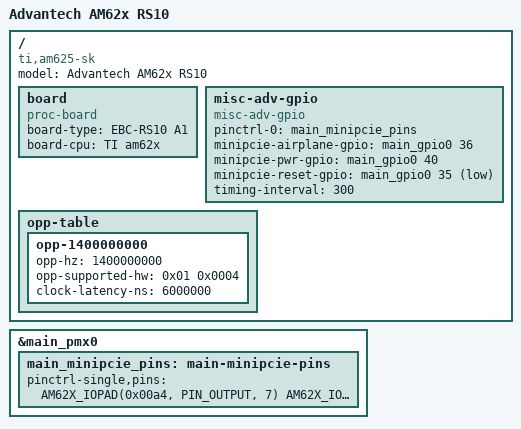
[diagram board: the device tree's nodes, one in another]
// SPDX-License-Identifier: GPL-2.0
/*
 * AM625 SK: https://www.ti.com/lit/zip/sprr448
 *
 * Copyright (C) 2021-2022 Texas Instruments Incorporated - https://www.ti.com/
 */

/dts-v1/;

#include <dt-bindings/leds/common.h>
#include <dt-bindings/gpio/gpio.h>
#include <dt-bindings/net/ti-dp83867.h>
#include "k3-am625.dtsi"
#include "k3-am62x-rs10-common.dtsi"

/ {
	compatible =  "ti,am625-sk", "ti,am625";
	model = "Advantech AM62x RS10";

    board {
        compatible = "proc-board";
        board-type = "EBC-RS10 A1";
        board-cpu = "TI am62x";
    };

    misc-adv-gpio {
        compatible = "misc-adv-gpio";
        pinctrl-names = "default";
        pinctrl-0 = <&main_minipcie_pins>;
        status = "okay";
        minipcie-airplane-gpio = <&main_gpio0 36 GPIO_ACTIVE_HIGH>;
        minipcie-pwr-gpio = <&main_gpio0 40 GPIO_ACTIVE_HIGH>;
        minipcie-reset-gpio = <&main_gpio0 35 GPIO_ACTIVE_LOW>;
        timing-interval = <300>;
    };

	opp-table {
		/* Add 1.4GHz OPP for am625-sk board. Requires VDD_CORE to be at 0.85V */
		opp-1400000000 {
			opp-hz = /bits/ 64 <1400000000>;
			opp-supported-hw = <0x01 0x0004>;
			clock-latency-ns = <6000000>;
		};
	};
};

&main_pmx0 {
	main_minipcie_pins: main-minipcie-pins {
		pinctrl-single,pins = <
			AM62X_IOPAD(0x00a4, PIN_OUTPUT, 7) /* GPMC0_DIR.GPIO0_40 */
			AM62X_IOPAD(0x0090, PIN_OUTPUT, 7) /* GPMC0_BE0N_CLE.GPIO0_35 */
			AM62X_IOPAD(0x0094, PIN_OUTPUT, 7) /* GPMC0_BE1N.GPIO0_36 */
		>;
	};
};
